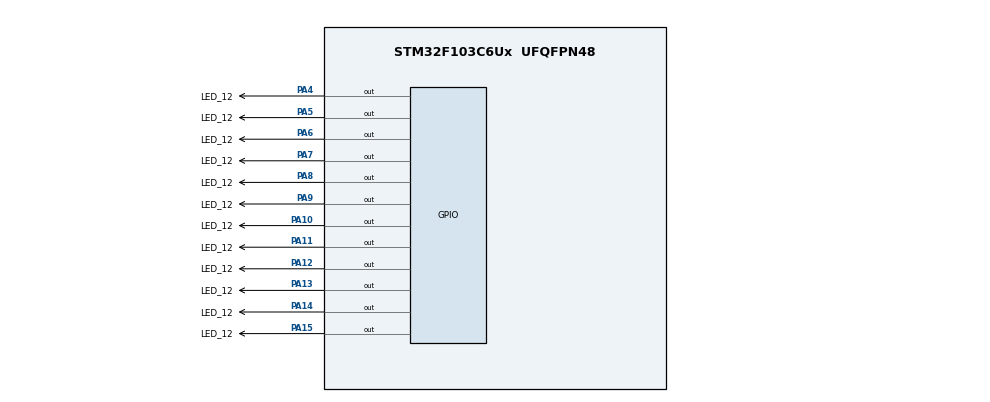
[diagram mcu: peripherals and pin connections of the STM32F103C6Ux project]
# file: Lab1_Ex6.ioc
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Mcu.Family=STM32F1
Mcu.Name=STM32F103C6Ux
Mcu.Package=UFQFPN48
NVIC.PriorityGroup=NVIC_PRIORITYGROUP_4
PA10.GPIO_Label=LED_12
PA10.PinState=GPIO_PIN_SET
PA10.Signal=GPIO_Output
PA11.GPIO_Label=LED_12
PA11.PinState=GPIO_PIN_SET
PA11.Signal=GPIO_Output
PA12.GPIO_Label=LED_12
PA12.PinState=GPIO_PIN_SET
PA12.Signal=GPIO_Output
PA13.GPIO_Label=LED_12
PA13.PinState=GPIO_PIN_SET
PA13.Signal=GPIO_Output
PA14.GPIO_Label=LED_12
PA14.PinState=GPIO_PIN_SET
PA14.Signal=GPIO_Output
PA15.GPIO_Label=LED_12
PA15.PinState=GPIO_PIN_SET
PA15.Signal=GPIO_Output
PA4.GPIO_Label=LED_12
PA4.PinState=GPIO_PIN_SET
PA4.Signal=GPIO_Output
PA5.GPIO_Label=LED_12
PA5.PinState=GPIO_PIN_SET
PA5.Signal=GPIO_Output
PA6.GPIO_Label=LED_12
PA6.PinState=GPIO_PIN_SET
PA6.Signal=GPIO_Output
PA7.GPIO_Label=LED_12
PA7.PinState=GPIO_PIN_SET
PA7.Signal=GPIO_Output
PA8.GPIO_Label=LED_12
PA8.PinState=GPIO_PIN_SET
PA8.Signal=GPIO_Output
PA9.GPIO_Label=LED_12
PA9.PinState=GPIO_PIN_SET
PA9.Signal=GPIO_Output
ProjectManager.HeapSize=0x200
ProjectManager.StackSize=0x400
ProjectManager.TargetToolchain=STM32CubeIDE
RCC.APB1Freq_Value=8000000
RCC.APB2Freq_Value=8000000
VP_SYS_VS_ND.Mode=No_Debug
board=custom

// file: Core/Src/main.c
/* USER CODE BEGIN Header */
/**
  ******************************************************************************
  * @file           : main.c
  * @brief          : Main program body
  ******************************************************************************
  * @attention
  *
  * <h2><center>&copy; Copyright (c) 2023 STMicroelectronics.
  * All rights reserved.</center></h2>
  *
  * This software component is licensed by ST under BSD 3-Clause license,
  * the "License"; You may not use this file except in compliance with the
  * License. You may obtain a copy of the License at:
  *                        opensource.org/licenses/BSD-3-Clause
  *
  ******************************************************************************
  */
/* USER CODE END Header */
#include "main.h"

void SystemClock_Config(void);
static void MX_GPIO_Init(void);

void clearAllclock(){
	for(int i=0;i<12;i++){
		HAL_GPIO_WritePin(GPIOA, LED_12_Pin <<(i), SET);
	}
}

void setNumberOnClock(int num){
	HAL_GPIO_WritePin(GPIOA, LED_12_Pin<<(num), RESET);
}
void clearNumberOnClock(int num){
	HAL_GPIO_WritePin(GPIOA, LED_12_Pin <<(num), SET);
}

int main(void)
{

  /* MCU Configuration--------------------------------------------------------*/

  /* Reset of all peripherals, Initializes the Flash interface and the Systick. */
  HAL_Init();

  /* Configure the system clock */
  SystemClock_Config();

  /* Initialize all configured peripherals */
  MX_GPIO_Init();

  /* Infinite loop */
  /* USER CODE BEGIN WHILE */

//    int counter=0;	//For Ex6+7+8+9
  /*Ex10*/
  int second = 0;
  int minute = 11;
  int hour = 10;
  int change_hour = 0;
  int change_minute = 0;
  setNumberOnClock(second);
  setNumberOnClock(minute);
  setNumberOnClock(hour);
  while (1)
  {
    /* USER CODE END WHILE */
	  // All pins were set to high at the beginning

	  /*Ex6+7+8+9*/
//	  int temp = counter %12;
////	  HAL_GPIO_WritePin(GPIOA, LED_12_Pin <<(temp), RESET);
//	  setNumberOnClock(temp);
//	  counter++;
//	  if(counter >12) {
//		  clearNumberOnClock(6);	// For Ex9 clear number on a specific pin
//		  clearAllclock();
//		  counter = 0;
//	  }
//	  HAL_Delay(1000);
	  /*Ex10*/
	  // Second
	  setNumberOnClock(second);
	  if(second == 0 )	clearNumberOnClock(11);
	  else if(second != 0)	clearNumberOnClock(second - 1);

	  // Minute
	  setNumberOnClock(minute);
	  if(minute ==0 && change_minute !=0) {
		  clearNumberOnClock(11);
		  change_minute =0;
	  }else if(minute !=0 && change_minute ==1) {
		  clearNumberOnClock(minute-1);
		  change_minute =0;
	  }

	  // Hour
	  setNumberOnClock(hour);
	  if(hour ==0 && change_hour !=0) {
		  clearNumberOnClock(11);
		  change_hour =0;
	  }else if(hour !=0 && change_hour ==1) {
		  clearNumberOnClock(hour-1);
		  change_hour =0;
	  }

	  if(second == 11){
		  second = 0;
		  minute++;
		  if(minute == 12){
			  minute = 0;
			  hour++;
			  if(hour==12){
				  hour = 0;
			  }
			  change_hour = 1;
		  }
		  change_minute = 1;
		  HAL_Delay(1000);
		  continue;
	  }

	  second++;
	  HAL_Delay(1000);

  }
}

void SystemClock_Config(void)
{
  RCC_OscInitTypeDef RCC_OscInitStruct = {0};
  RCC_ClkInitTypeDef RCC_ClkInitStruct = {0};

  /** Initializes the RCC Oscillators according to the specified parameters
  * in the RCC_OscInitTypeDef structure.
  */
  RCC_OscInitStruct.OscillatorType = RCC_OSCILLATORTYPE_HSI;
  RCC_OscInitStruct.HSIState = RCC_HSI_ON;
  RCC_OscInitStruct.HSICalibrationValue = RCC_HSICALIBRATION_DEFAULT;
  RCC_OscInitStruct.PLL.PLLState = RCC_PLL_NONE;
  if (HAL_RCC_OscConfig(&RCC_OscInitStruct) != HAL_OK)
  {
    Error_Handler();
  }
  /** Initializes the CPU, AHB and APB buses clocks
  */
  RCC_ClkInitStruct.ClockType = RCC_CLOCKTYPE_HCLK|RCC_CLOCKTYPE_SYSCLK
                              |RCC_CLOCKTYPE_PCLK1|RCC_CLOCKTYPE_PCLK2;
  RCC_ClkInitStruct.SYSCLKSource = RCC_SYSCLKSOURCE_HSI;
  RCC_ClkInitStruct.AHBCLKDivider = RCC_SYSCLK_DIV1;
  RCC_ClkInitStruct.APB1CLKDivider = RCC_HCLK_DIV1;
  RCC_ClkInitStruct.APB2CLKDivider = RCC_HCLK_DIV1;

  if (HAL_RCC_ClockConfig(&RCC_ClkInitStruct, FLASH_LATENCY_0) != HAL_OK)
  {
    Error_Handler();
  }
}

static void MX_GPIO_Init(void)
{
  GPIO_InitTypeDef GPIO_InitStruct = {0};

  /* GPIO Ports Clock Enable */
  __HAL_RCC_GPIOA_CLK_ENABLE();

  /*Configure GPIO pin Output Level */
  HAL_GPIO_WritePin(GPIOA, LED_12_Pin|LED_12A5_Pin|LED_12A6_Pin|LED_12A7_Pin
                          |LED_12A8_Pin|LED_12A9_Pin|LED_12A10_Pin|LED_12A11_Pin
                          |LED_12A12_Pin|LED_12A13_Pin|LED_12A14_Pin|LED_12A15_Pin, GPIO_PIN_SET);

  /*Configure GPIO pins : LED_12_Pin LED_12A5_Pin LED_12A6_Pin LED_12A7_Pin
                           LED_12A8_Pin LED_12A9_Pin LED_12A10_Pin LED_12A11_Pin
                           LED_12A12_Pin LED_12A13_Pin LED_12A14_Pin LED_12A15_Pin */
  GPIO_InitStruct.Pin = LED_12_Pin|LED_12A5_Pin|LED_12A6_Pin|LED_12A7_Pin
                          |LED_12A8_Pin|LED_12A9_Pin|LED_12A10_Pin|LED_12A11_Pin
                          |LED_12A12_Pin|LED_12A13_Pin|LED_12A14_Pin|LED_12A15_Pin;
  GPIO_InitStruct.Mode = GPIO_MODE_OUTPUT_PP;
  GPIO_InitStruct.Pull = GPIO_NOPULL;
  GPIO_InitStruct.Speed = GPIO_SPEED_FREQ_LOW;
  HAL_GPIO_Init(GPIOA, &GPIO_InitStruct);

}

void Error_Handler(void)
{
  __disable_irq();
  while (1)
  {
  }
}

/************************ (C) COPYRIGHT STMicroelectronics *****END OF FILE****/
